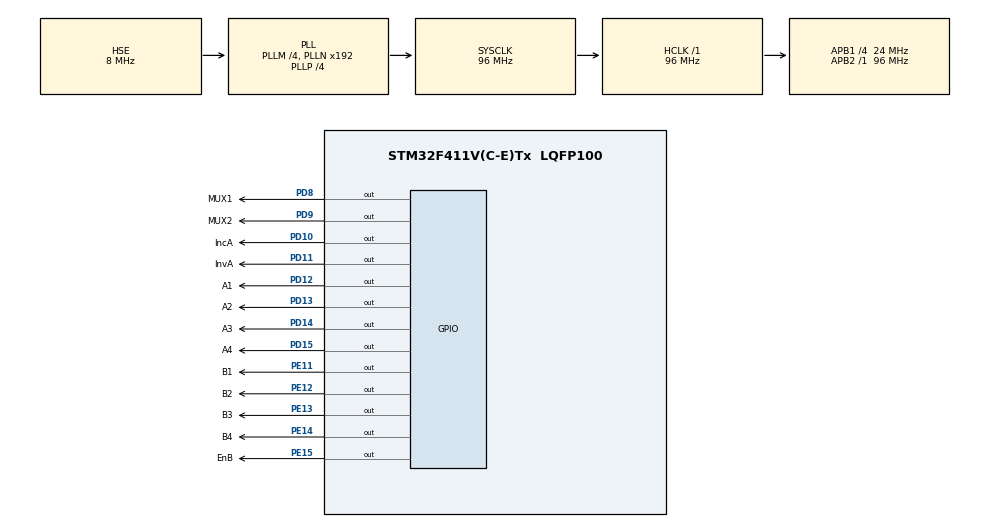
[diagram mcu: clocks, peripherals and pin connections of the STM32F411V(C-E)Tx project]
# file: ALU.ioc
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Mcu.Family=STM32F4
Mcu.Name=STM32F411V(C-E)Tx
Mcu.Package=LQFP100
NVIC.PriorityGroup=NVIC_PRIORITYGROUP_0
PA13.Mode=Serial_Wire
PA13.Signal=SYS_JTMS-SWDIO
PA14.Mode=Serial_Wire
PA14.Signal=SYS_JTCK-SWCLK
PC14-OSC32_IN.Mode=LSE-External-Oscillator
PC14-OSC32_IN.Signal=RCC_OSC32_IN
PC15-OSC32_OUT.Mode=LSE-External-Oscillator
PC15-OSC32_OUT.Signal=RCC_OSC32_OUT
PD10.GPIO_Label=IncA
PD10.Signal=GPIO_Output
PD11.GPIO_Label=InvA
PD11.Signal=GPIO_Output
PD12.GPIO_Label=A1
PD12.Signal=GPIO_Output
PD13.GPIO_Label=A2
PD13.Signal=GPIO_Output
PD14.GPIO_Label=A3
PD14.Signal=GPIO_Output
PD15.GPIO_Label=A4
PD15.Signal=GPIO_Output
PD8.GPIO_Label=MUX1
PD8.Signal=GPIO_Output
PD9.GPIO_Label=MUX2
PD9.Signal=GPIO_Output
PE11.GPIO_Label=B1
PE11.Signal=GPIO_Output
PE12.GPIO_Label=B2
PE12.Signal=GPIO_Output
PE13.GPIO_Label=B3
PE13.Signal=GPIO_Output
PE14.GPIO_Label=B4
PE14.Signal=GPIO_Output
PE15.GPIO_Label=EnB
PE15.Signal=GPIO_Output
PH0\ -\ OSC_IN.Mode=HSE-External-Oscillator
PH0\ -\ OSC_IN.Signal=RCC_OSC_IN
PH1\ -\ OSC_OUT.Mode=HSE-External-Oscillator
PH1\ -\ OSC_OUT.Signal=RCC_OSC_OUT
ProjectManager.HeapSize=0x200
ProjectManager.StackSize=0x400
ProjectManager.TargetToolchain=STM32CubeIDE
RCC.48MHZClocksFreq_Value=48000000
RCC.AHBFreq_Value=96000000
RCC.APB1CLKDivider=RCC_HCLK_DIV4
RCC.APB1Freq_Value=24000000
RCC.APB1TimFreq_Value=48000000
RCC.APB2Freq_Value=96000000
RCC.APB2TimFreq_Value=96000000
RCC.CortexFreq_Value=96000000
RCC.HCLKFreq_Value=96000000
RCC.HSE_VALUE=8000000
RCC.HSI_VALUE=16000000
RCC.PLLI2SM=5
RCC.PLLI2SN=200
RCC.PLLM=4
RCC.PLLP=RCC_PLLP_DIV4
RCC.PLLQ=8
RCC.PLLSourceVirtual=RCC_PLLSOURCE_HSE
RCC.SYSCLKFreq_VALUE=96000000
RCC.SYSCLKSource=RCC_SYSCLKSOURCE_PLLCLK
RCC.VCOOutputFreq_Value=384000000
board=STM32F411E-DISCO

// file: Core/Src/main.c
/* USER CODE BEGIN Header */
/**
  ******************************************************************************
  * @file           : main.c
  * @brief          : Main program body
  ******************************************************************************
  * @attention
  *
  * Copyright (c) 2022 STMicroelectronics.
  * All rights reserved.
  *
  * This software is licensed under terms that can be found in the LICENSE file
  * in the root directory of this software component.
  * If no LICENSE file comes with this software, it is provided AS-IS.
  *
  ******************************************************************************
  */
/* USER CODE END Header */
#include "main.h"
#include "gpio.h"

void SystemClock_Config(void);

/* USER CODE BEGIN 0 */
//int* decimalToBinary(int num) {
//	int binaryNum[4];
//    if (num == 0) {
//    	int binaryNum[4] = {0,0,0,0};
//        return;
//    }
//
//   // Stores binary representation of number.
//    // Assuming 32 bit integer.
//   int i=0;
//
//   for ( ;num > 0; ){
//      binaryNum[i++] = num % 2;
//      num /= 2;
//   }
//   return binaryNum;
//
//   // Printing array in reverse order.
//}
/* USER CODE END 0 */

int main(void)
{

  /* MCU Configuration--------------------------------------------------------*/

  /* Reset of all peripherals, Initializes the Flash interface and the Systick. */
  HAL_Init();

  /* Configure the system clock */
  SystemClock_Config();

  /* Initialize all configured peripherals */
  MX_GPIO_Init();

  /* Infinite loop */
  /* USER CODE BEGIN WHILE */
  while (1)
  {
	  HAL_GPIO_WritePin(GPIOE, B1_Pin, 1);
	  HAL_GPIO_WritePin(GPIOE, B2_Pin, 0);
	  HAL_GPIO_WritePin(GPIOE, B3_Pin, 0);
	  HAL_GPIO_WritePin(GPIOE, B4_Pin, 1);
	  HAL_GPIO_WritePin(GPIOE, EnB_Pin, 1);

//	  for(int a4=0;a4<2;++a4){
//		  for(int a3=0;a3<2;++a3){
//			  for(int a2=0;a2<2;++a2){
//				  for(int a1=0; a1<2;a1++){
//					  HAL_GPIO_WritePin(GPIOD, A1_Pin, a1);
//					  HAL_GPIO_WritePin(GPIOD, A2_Pin, a2);
//					  HAL_GPIO_WritePin(GPIOD, A3_Pin, a3);
//					  HAL_GPIO_WritePin(GPIOD, A4_Pin, a4);
//					  HAL_GPIO_WritePin(GPIOD, InvA_Pin, GPIO_PIN_RESET);
//					  HAL_Delay(3000);
//				  }
//			  }
//		  }
//	  }
	  HAL_GPIO_WritePin(GPIOD, InvA_Pin, 0);
	  HAL_GPIO_WritePin(GPIOD, IncA_Pin, 0);
	  HAL_GPIO_WritePin(GPIOD, A1_Pin, 1);
	  HAL_GPIO_WritePin(GPIOD, A2_Pin, 1);
	  HAL_GPIO_WritePin(GPIOD, A3_Pin, 1);
	  HAL_GPIO_WritePin(GPIOD, A4_Pin, 1);
	  HAL_GPIO_WritePin(GPIOD, MUX1_Pin, 0);
	  HAL_GPIO_WritePin(GPIOD, MUX2_Pin, 0);

    /* USER CODE END WHILE */

  }
}

void SystemClock_Config(void)
{
  RCC_OscInitTypeDef RCC_OscInitStruct = {0};
  RCC_ClkInitTypeDef RCC_ClkInitStruct = {0};

  /** Configure the main internal regulator output voltage
  */
  __HAL_RCC_PWR_CLK_ENABLE();
  __HAL_PWR_VOLTAGESCALING_CONFIG(PWR_REGULATOR_VOLTAGE_SCALE1);

  /** Initializes the RCC Oscillators according to the specified parameters
  * in the RCC_OscInitTypeDef structure.
  */
  RCC_OscInitStruct.OscillatorType = RCC_OSCILLATORTYPE_HSE;
  RCC_OscInitStruct.HSEState = RCC_HSE_ON;
  RCC_OscInitStruct.PLL.PLLState = RCC_PLL_ON;
  RCC_OscInitStruct.PLL.PLLSource = RCC_PLLSOURCE_HSE;
  RCC_OscInitStruct.PLL.PLLM = 4;
  RCC_OscInitStruct.PLL.PLLN = 192;
  RCC_OscInitStruct.PLL.PLLP = RCC_PLLP_DIV4;
  RCC_OscInitStruct.PLL.PLLQ = 8;
  if (HAL_RCC_OscConfig(&RCC_OscInitStruct) != HAL_OK)
  {
    Error_Handler();
  }

  /** Initializes the CPU, AHB and APB buses clocks
  */
  RCC_ClkInitStruct.ClockType = RCC_CLOCKTYPE_HCLK|RCC_CLOCKTYPE_SYSCLK
                              |RCC_CLOCKTYPE_PCLK1|RCC_CLOCKTYPE_PCLK2;
  RCC_ClkInitStruct.SYSCLKSource = RCC_SYSCLKSOURCE_PLLCLK;
  RCC_ClkInitStruct.AHBCLKDivider = RCC_SYSCLK_DIV1;
  RCC_ClkInitStruct.APB1CLKDivider = RCC_HCLK_DIV4;
  RCC_ClkInitStruct.APB2CLKDivider = RCC_HCLK_DIV1;

  if (HAL_RCC_ClockConfig(&RCC_ClkInitStruct, FLASH_LATENCY_3) != HAL_OK)
  {
    Error_Handler();
  }
}

void Error_Handler(void)
{
  __disable_irq();
  while (1)
  {
  }
}
